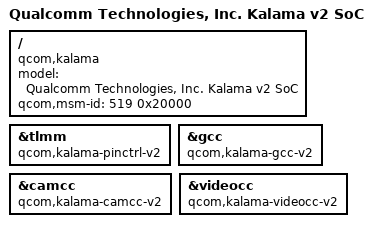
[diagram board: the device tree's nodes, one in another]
#include "kalama.dtsi"

/ {
	model = "Qualcomm Technologies, Inc. Kalama v2 SoC";
	compatible = "qcom,kalama";
	qcom,msm-id = <519 0x20000>;
};

&tlmm {
	compatible = "qcom,kalama-pinctrl-v2";
};

&gcc {
	compatible = "qcom,kalama-gcc-v2", "syscon";
};

&camcc {
	compatible = "qcom,kalama-camcc-v2", "syscon";
};

&videocc {
	compatible = "qcom,kalama-videocc-v2", "syscon";
};
